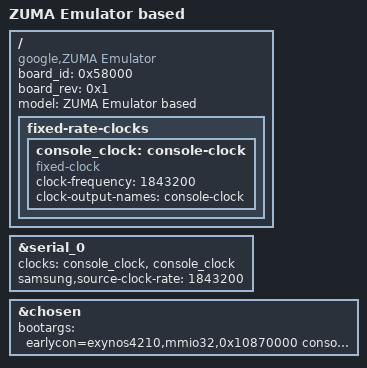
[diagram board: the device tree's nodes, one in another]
// SPDX-License-Identifier: GPL-2.0-only
/*
 * Zuma on emulator device tree source
 *
 * Copyright 2020-2021 Google LLC
 */

/dts-v1/;
/plugin/;

/ {
	board_id = <0x58000>;
	board_rev = <0x1>;
	fragment@boardbase {
		target-path="/";
		__overlay__ {
			model = "ZUMA Emulator based";
			compatible = "google,ZUMA Emulator", "google,ZUMA";
			fixed-rate-clocks {
				console_clock: console-clock {
					compatible = "fixed-clock";
					#clock-cells = <0>;
					clock-frequency = <1843200>;
					clock-output-names = "console-clock";
				};
			};
		};
	};
};

&serial_0 {
	status = "okay";
	clocks = <&console_clock>, <&console_clock>;
	samsung,source-clock-rate = <1843200>;
};

&chosen {
	bootargs = "earlycon=exynos4210,mmio32,0x10870000 console=ttySAC0,115200n8 clocksource=arch_sys_counter root=/dev/ram0 rw ramdisk_size=65536 initrd=0x84000000,32M androidboot.hardware=zuma androidboot.hardware.platform=zuma androidboot.selinux=permissive androidboot.debug_level=0x4948 firmware_class.path=/vendor/firmware clk_ignore_unused loop.max_part=7 coherent_pool=4M no_console_suspend nokaslr softlockup_panic=1 sysrq_always_enabled mem=512M maxcpus=1 androidboot.first_stage_console=1 androidboot.force_normal_boot=1 maxcpus=1 slub_debug=- printk.devkmsg=on nosmp cpuidle.off=1 arm64.nopauth arm64.nomte kasan=off panic_on_warm=1";
};
